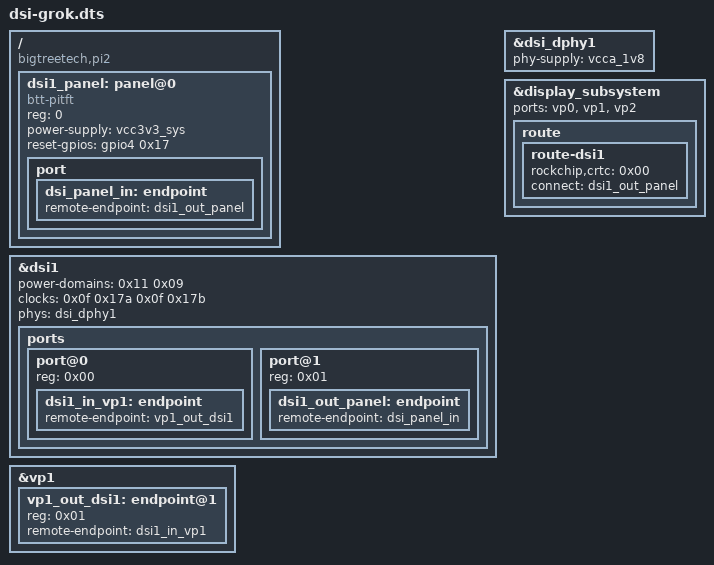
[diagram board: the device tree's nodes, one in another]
/dts-v1/;
/plugin/;

/ {
	compatible = "bigtreetech,pi2", "rockchip,rk3566";

	/* Fragment 0: Enable and configure DSI1 controller at fe070000 */
	fragment@0 {
		target = <&dsi1>;// Targets /dsi@fe070000 as DSI1
		__overlay__ {
			status = "okay";
			power-domains = <0x11 0x09>;// Matches power domain from dsi-does-not-work.dts
			clocks = <0x0f 0x17a 0x0f 0x17b>;// DSI and pclk clocks from clock-controller@fdd20000
			clock-names = "dsi", "pclk";
			phys = <&dsi_dphy1>;// Links to phy@fe860000, the PHY for DSI1
			phy-names = "dphy";

			ports {
				#address-cells = <0x01>;
				#size-cells = <0x00>;

				/* Input port from VOP (VP1) */
				port@0 {
					reg = <0x00>;
					dsi1_in_vp1: endpoint {
						remote-endpoint = <&vp1_out_dsi1>;
					};
				};

				/* Output port to the panel */
				port@1 {
					reg = <0x01>;
					dsi1_out_panel: endpoint {
						remote-endpoint = <&dsi_panel_in>;
					};
				};
			};
		};
	};

	/* Fragment 1: Configure DSI1 PHY at fe860000 */
	fragment@1 {
		target = <&dsi_dphy1>;// Targets /phy@fe860000, the PHY for DSI1
		__overlay__ {
			status = "okay";
			phy-supply = <&vcca_1v8>;// Matches vcca_1v8 (phandle 0xa7) from dsi-does-not-work.dts
			/* Ensure PHY is fully enabled and matches working configuration */
		};
	};

	/* Fragment 2: Link VOP VP1 to DSI1 */
	fragment@2 {
		target = <&vp1>;// Targets /vop@fe040000/ports/port@1 (VP1)
		__overlay__ {
			vp1_out_dsi1: endpoint@1 {
				reg = <0x01>;// Endpoint 1 is typically used for DSI1
				remote-endpoint = <&dsi1_in_vp1>;
			};
		};
	};

	/* Fragment 3: Ensure display-subsystem routes to DSI1 */
	fragment@3 {
		target = <&display_subsystem>;
		__overlay__ {
			ports = <&vp0 &vp1 &vp2>;// Ensure all VOP ports are available
			route {
				route-dsi1 {
					status = "okay";// Already okay in base DTS, reinforced here
					rockchip,crtc = <0x00>;// VP0 as primary CRTC, adjust if needed
					connect = <&dsi1_out_panel>;// Connects to panel endpoint
				};
			};
		};
	};

	/* Fragment 4: Add DSI1 panel node */
	fragment@4 {
		target-path = "/";
		__overlay__ {
			dsi1_panel: panel@0 {
				compatible = "btt-pitft";
				// compatible = "sitronix,st7789v";// Common DSI panel, adjust as needed
				reg = <0>;// DSI channel 0
				status = "okay";
				power-supply = <&vcc3v3_sys>;// Example regulator, adjust per hardware
				reset-gpios = <&gpio4 0x17 0x00>;// Example GPIO4 pin 23, adjust per schematic
				/* Add backlight if applicable */
				// backlight = <&backlight>;

				port {
					dsi_panel_in: endpoint {
						remote-endpoint = <&dsi1_out_panel>;
					};
				};
			};
		};
	};
};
